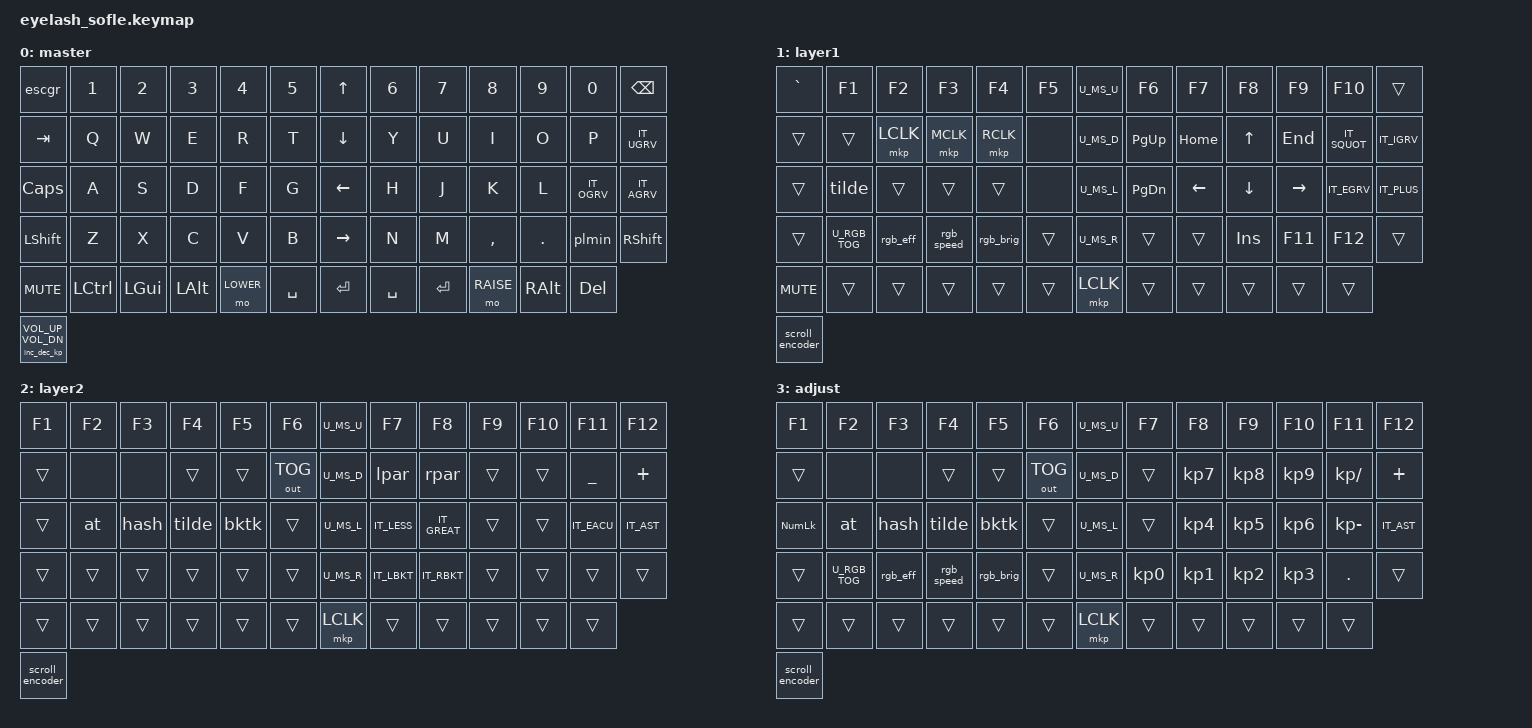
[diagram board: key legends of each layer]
/*
     _____        __ _          _   __           _                         _
    /  ___|      / _| |        | | / /          | |                       | |
    \ `--.  ___ | |_| | ___    | |/ /  ___ _   _| |__   ___   __ _ _ __ __| |
     `--. \/ _ \|  _| |/ _ \   |    \ / _ \ | | | '_ \ / _ \ / _` | '__/ _` |
    /\__/ / (_) | | | |  __/   | |\  \  __/ |_| | |_) | (_) | (_| | | | (_| |
    \____/ \___/|_| |_|\___|   \_| \_/\___|\__, |_.__/ \___/ \__,_|_|  \__,_|
                                            __/ |
                                           |___/
*/
#include <behaviors.dtsi>
#include <dt-bindings/zmk/bt.h>
#include <dt-bindings/zmk/ext_power.h>
#include <dt-bindings/zmk/keys.h>
#include <dt-bindings/zmk/rgb.h>
#include <dt-bindings/zmk/outputs.h>

#define BASE 0
#define LOWER 1
#define RAISE 2
#define ADJUST 3
#define SYS 4
#define FN 5

// Make the keymap section less noisy
#define XXX &none
#define ___ &trans

#include "matrix.h"

// Needed for my sanity generating the keymap layout
#ifndef KEYMAP_DRAWER
	#include "keycodes.h"
#endif

#include "helpers.h"
#include "mouse.dtsi"
#include "combos.dtsi"
#include "macros.dtsi"

/* Global defaults */

// Activate ADJUST layer by pressing raise and lower
ZMK_CONDITIONAL_LAYER(adjust, LOWER RAISE, ADJUST)

// ╭─────────┬─────────┬─────────┬─────────┬─────────┬─────────╮                                 ╭─────────┬─────────┬─────────┬─────────┬─────────┬─────────╮
// │ ESC | \ │  1      │ 2       │ 3       │ 4       │ 5       │                                 │ 6       │ 7       │ 8       │ 9       │ 0       │BACKSPACE│
// ├─────────┼─────────┼─────────┼─────────┼─────────┼─────────┤                                 ├─────────┼─────────┼─────────┼─────────┼─────────┼─────────┤
// │ TAB     │  Q      │ W       │ E       │ R       │ T       │                                 │ Y       │ U       │ I       │ O       │ P       │ ù       │
// ├─────────┼─────────┼─────────┼─────────┼─────────┼─────────┤                                 ├─────────┼─────────┼─────────┼─────────┼─────────┼─────────┤
// │ CAPS    │  A      │ S       │ D       │ F       │ G       │                                 │ H       │ J       │ K       │ L       │ ò       │ à       │
// ├─────────┼─────────┼─────────┼─────────┼─────────┼─────────┼─────────╮             ╭─────────┼─────────┼─────────┼─────────┼─────────┼─────────┼─────────┤
// │ LSHIFT  │  Z      │ X       │ C       │ V       │ B       │ MUTE    │             │↑↓  ←  → │ N       │ M       │ ,       │ .       │ -       │ RSHIFT  │
// ╰─────────┬─────────┬─────────┬─────────┬─────────┬─────────┬─────────╯             ╰─────────┬─────────┬─────────┬─────────┬─────────┬─────────┬─────────╯
//           │  LCTRL  │ LGUI    │ LALT    │ MO(1)   │ SPACE   │                                 │ SPACE   │ ENTER   │ MO(2)   │ RALT    │ DELETE  │
//           ╰─────────┴─────────┴─────────┴─────────┴─────────╯                                 ╰─────────┴─────────┴─────────┴─────────┴─────────╯

ZMK_LAYER(master,
    &escgr     &kp N1        &kp N2        &kp N3        &kp N4        &kp N5        &kp UP      &kp N6        &kp N7        &kp N8        &kp N9        &kp N0        &kp BACKSPACE
    &kp TAB    &kp Q         &kp W         &kp E         &kp R         &kp T         &kp DOWN    &kp Y         &kp U         &kp I         &kp O         &kp P         &kp IT_UGRV
    &kp CAPS   &kp A         &kp S         &kp D         &kp F         &kp G         &kp LEFT    &kp H         &kp J         &kp K         &kp L         &kp IT_OGRV   &kp IT_AGRV
    &kp LSHFT  &kp Z         &kp X         &kp C         &kp V         &kp B         &kp RIGHT   &kp N         &kp M         &kp COMMA     &kp DOT       &plmin        &kp RSHIFT
    &kp C_MUTE &kp LCTRL     &kp LGUI      &kp LALT      &mo LOWER     &kp SPACE     &kp ENTER   &kp SPACE     &kp ENTER     &mo RAISE     &kp RALT      &kp DELETE
    , &inc_dec_kp C_VOLUME_UP C_VOL_DN
)


// ╭─────────┬─────────┬─────────┬─────────┬─────────┬─────────╮                                 ╭─────────┬─────────┬─────────┬─────────┬─────────┬─────────╮
// │ GRESC   │ F1      │ F2      │ F3      │ F4      │ F5      │                                 │ F6      │ F7      │ F8      │ F9      │ F10     │         │
// ├─────────┼─────────┼─────────┼─────────┼─────────┼─────────┤                                 ├─────────┼─────────┼─────────┼─────────┼─────────┼─────────┤
// │         │ GRAVE   │ M_LCLK  │ M_MCLK  │ M_RCLK  │ NONE    │                                 │ PG_UP   │ HOME    │  ↑      │ END     │ '       │ ì       │
// ├─────────┼─────────┼─────────┼─────────┼─────────┼─────────┤                                 ├─────────┼─────────┼─────────┼─────────┼─────────┼─────────┤
// │         │ TILDE   │         │         │         │ NONE    │                                 │ PG_DOWN │ ←       │  ↓      │  →      │ [       │ ]       │
// ├─────────┼─────────┼─────────┼─────────┼─────────┼─────────┼─────────╮             ╭─────────┼─────────┼─────────┼─────────┼─────────┼─────────┼─────────┤
// │         │ RGB_TOG │   RGB   │   RGB   │   RGB   │         │  MUTE   │             │↑↓  ←  → │         │         │ INSERT  │ F11     │ F12     │         │
// │         │         │  EFFECT │  SPEED  │  BRIGHT │         │         │             │ M_LCLK  │         │         │         │         │         │         │
// ╰─────────┬─────────┬─────────┬─────────┬─────────┬─────────┬─────────╯             ╰─────────┬─────────┬─────────┬─────────┬─────────┬─────────┬─────────╯
//           │         │         │         │         │         │                                 │         │         │         │         │         │
//           ╰─────────┴─────────┴─────────┴─────────┴─────────╯                                 ╰─────────┴─────────┴─────────┴─────────┴─────────╯
// TODO: Rethink the layout as it seems that some keys are currently wasted
ZMK_LAYER(layer1,
    &kp GRAVE    &kp F1        &kp F2        &kp F3        &kp F4        &kp F5       U_MS_U     &kp F6       &kp F7       &kp F8        &kp F9       &kp F10       ___
    ___          ___           &mkp LCLK     &mkp MCLK     &mkp RCLK     XXX          U_MS_D     &kp PG_UP    &kp HOME     &kp UP        &kp END      &kp IT_SQUOT  &kp IT_IGRV
    ___          &tilde        ___           ___           ___           XXX          U_MS_L     &kp PG_DN    &kp LEFT     &kp DOWN      &kp RIGHT    &kp IT_EGRV   &kp IT_PLUS
    ___          U_RGB_TOG     &rgb_eff      &rgb_speed    &rgb_brig     ___          U_MS_R     ___          ___          &kp INSERT    &kp F11      &kp F12       ___
    &kp C_MUTE   ___           ___           ___           ___           ___          &mkp LCLK  ___          ___          ___           ___          ___
    , &scroll_encoder
)

// ╭─────────┬─────────┬─────────┬─────────┬─────────┬─────────╮                                 ╭─────────┬─────────┬─────────┬─────────┬─────────┬─────────╮
// │ F1      │ F2      │ F3      │ F4      │ F5      │ F6      │                                 │ F7      │ F8      │ F9      │ F10     │ F11     │ F12     │
// ├─────────┼─────────┼─────────┼─────────┼─────────┼─────────┤                                 ├─────────┼─────────┼─────────┼─────────┼─────────┼─────────┤
// │         │ NONE    │ NONE    │         │         │ OUT_TOG │                                 │         │         │         │         │  _      │ +       │
// ├─────────┼─────────┼─────────┼─────────┼─────────┼─────────┤                                 ├─────────┼─────────┼─────────┼─────────┼─────────┼─────────┤
// │         │ @       │ #       │ ~       │ `       │         │                                 │ <       │ >       │         │         │  é      │ *       │
// ├─────────┼─────────┼─────────┼─────────┼─────────┼─────────┼─────────╮             ╭─────────┼─────────┼─────────┼─────────┼─────────┼─────────┼─────────┤
// │         │         │         │         │         │         │         │             │↑↓  ←  → │ {       │ }       │ NONE    │ NONE    │ RALT    │         │
// │         │         │         │         │         │         │         │             │  M_LCLK │         │         │         │         │         │         │
// ╰─────────┬─────────┬─────────┬─────────┬─────────┬─────────┬─────────╯             ╰─────────┬─────────┬─────────┬─────────┬─────────┬─────────┬─────────╯
//           │         │         │         │         │         │                                 │         │         │         │         │         │
//           ╰─────────┴─────────┴─────────┴─────────┴─────────╯                                 ╰─────────┴─────────┴─────────┴─────────┴─────────╯
ZMK_LAYER(layer2,
    &kp F1       &kp F2       &kp F3       &kp F4        &kp F5       &kp F6        U_MS_U     &kp F7       &kp F8       &kp F9      &kp F10      &kp F11       &kp F12
    ___          XXX          XXX          ___           ___          &out OUT_TOG  U_MS_D     &lpar        &rpar        ___         ___          &kp UNDER     &kp PLUS
    ___          &at          &hash        &tilde        &bktk        ___           U_MS_L     &kp IT_LESS  &kp IT_GREAT ___         ___          &kp IT_EACU   &kp IT_AST
    ___          ___          ___          ___           ___          ___           U_MS_R     &kp IT_LBKT  &kp IT_RBKT  ___         ___          ___            ___
    ___          ___          ___          ___           ___          ___           &mkp LCLK   ___           ___        ___         ___          ___
    , &scroll_encoder
)

// ╭─────────┬─────────┬─────────┬─────────┬─────────┬─────────╮                                 ╭─────────┬─────────┬─────────┬─────────┬─────────┬─────────╮
// │ F1      │ F2      │ F3      │ F4      │ F5      │ F6      │                                 │ F7      │ F8      │ F9      │ F10     │ F11     │ F12     │
// ├─────────┼─────────┼─────────┼─────────┼─────────┼─────────┤                                 ├─────────┼─────────┼─────────┼─────────┼─────────┼─────────┤
// │         │ NONE    │ NONE    │         │         │ OUT_TOG │                                 │         │  7      │  8      │  9      │  /      │ +       │
// ├─────────┼─────────┼─────────┼─────────┼─────────┼─────────┤                                 ├─────────┼─────────┼─────────┼─────────┼─────────┼─────────┤
// │NUM LOCK │ @       │ #       │ ~       │ `       │         │                                 │         │  4      │  5      │  6      │  -      │ ]       │
// ├─────────┼─────────┼─────────┼─────────┼─────────┼─────────┼─────────╮             ╭─────────┼─────────┼─────────┼─────────┼─────────┼─────────┼─────────┤
// │         │ RGB_TOG │   RGB   │   RGB   │   RGB   │         │  MUTE   │             │↑↓  ←  → │  0      │  1      │  2      │  3      │  .      │         │
// │         │         │  EFFECT │  SPEED  │  BRIGHT │         │         │             │ M_LCLK  │         │         │         │         │         │         │
// ╰─────────┬─────────┬─────────┬─────────┬─────────┬─────────┬─────────╯             ╰─────────┬─────────┬─────────┬─────────┬─────────┬─────────┬─────────╯
//           │         │         │         │         │         │                                 │         │         │         │         │         │
//           ╰─────────┴─────────┴─────────┴─────────┴─────────╯                                 ╰─────────┴─────────┴─────────┴─────────┴─────────╯
ZMK_LAYER(adjust,
    &kp F1       &kp F2       &kp F3       &kp F4        &kp F5      &kp F6        U_MS_U     &kp F7       &kp F8      &kp F9      &kp F10     &kp F11       &kp F12
    ___          XXX          XXX          ___           ___         &out OUT_TOG  U_MS_D     ___          &kp KP_N7   &kp KP_N8   &kp KP_N9   &kp KP_SLASH  &kp PLUS
    &kp KP_NUM   &at          &hash        &tilde        &bktk        ___          U_MS_L     ___          &kp KP_N4   &kp KP_N5   &kp KP_N6   &kp KP_MINUS  &kp IT_AST
    ___          U_RGB_TOG    &rgb_eff     &rgb_speed    &rgb_brig    ___          U_MS_R     &kp KP_N0    &kp KP_N1   &kp KP_N2   &kp KP_N3   &kp DOT       ___
    ___          ___          ___          ___           ___          ___          &mkp LCLK  ___          ___         ___         ___         ___
    , &scroll_encoder
)
